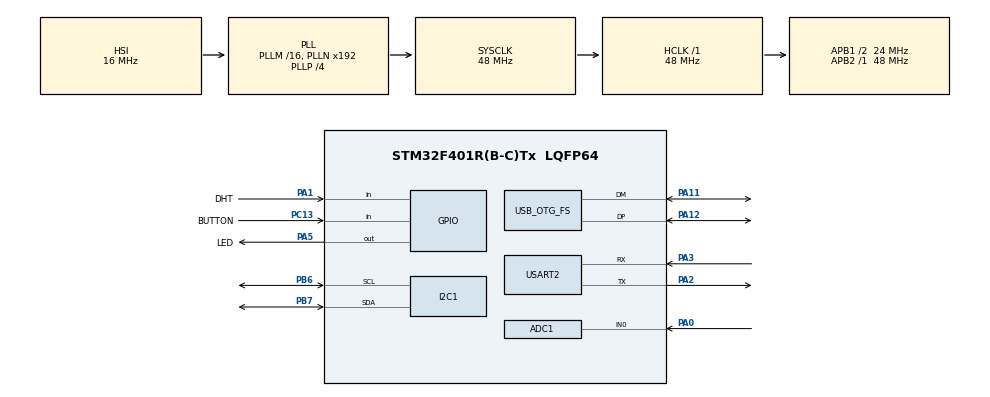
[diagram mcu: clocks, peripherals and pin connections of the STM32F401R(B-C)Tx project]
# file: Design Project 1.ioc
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ADC1.Channel-0\#ChannelRegularConversion=ADC_CHANNEL_0
ADC1.NbrOfConversionFlag=1
ADC1.Rank-0\#ChannelRegularConversion=1
ADC1.SamplingTime-0\#ChannelRegularConversion=ADC_SAMPLETIME_3CYCLES
ADC1.master=1
FREERTOS.Tasks01=defaultTask,24,128,StartDefaultTask,Default,NULL,Dynamic,NULL,NULL
Mcu.Family=STM32F4
Mcu.Name=STM32F401R(B-C)Tx
Mcu.Package=LQFP64
NVIC.OTG_FS_IRQn=true\:5\:0\:false\:false\:true\:true\:false\:true\:true
NVIC.PriorityGroup=NVIC_PRIORITYGROUP_4
NVIC.USART2_IRQn=true\:5\:0\:false\:false\:true\:true\:true\:true\:true
PA0-WKUP.Signal=ADCx_IN0
PA1.GPIO_Label=DHT
PA1.GPIO_PuPd=GPIO_PULLUP
PA1.Signal=GPIO_Input
PA11.Mode=Device_Only
PA11.Signal=USB_OTG_FS_DM
PA12.Mode=Device_Only
PA12.Signal=USB_OTG_FS_DP
PA2.Mode=Asynchronous
PA2.Signal=USART2_TX
PA3.Mode=Asynchronous
PA3.Signal=USART2_RX
PA5.GPIO_Label=LED
PA5.Signal=GPIO_Output
PB6.Mode=I2C
PB6.Signal=I2C1_SCL
PB7.Mode=I2C
PB7.Signal=I2C1_SDA
PC13-ANTI_TAMP.GPIO_Label=BUTTON
PC13-ANTI_TAMP.GPIO_PuPd=GPIO_PULLUP
PC13-ANTI_TAMP.Signal=GPIO_Input
ProjectManager.HeapSize=0x200
ProjectManager.StackSize=0x400
ProjectManager.TargetToolchain=STM32CubeIDE
RCC.AHBFreq_Value=48000000
RCC.APB1CLKDivider=RCC_HCLK_DIV2
RCC.APB1Freq_Value=24000000
RCC.APB1TimFreq_Value=48000000
RCC.APB2Freq_Value=48000000
RCC.APB2TimFreq_Value=48000000
RCC.CortexFreq_Value=48000000
RCC.HCLKFreq_Value=48000000
RCC.HSE_VALUE=25000000
RCC.HSI_VALUE=16000000
RCC.LSE_VALUE=32768
RCC.PLLP=RCC_PLLP_DIV4
RCC.PLLSource=RCC_PLLSOURCE_HSI
RCC.PLLSourceVirtualString=RCC_PLLSOURCE_HSI
RCC.SYSCLKFreq_VALUE=48000000
RCC.SYSCLKSource=RCC_SYSCLKSOURCE_PLLCLK
RCC.VCOOutputFreq_Value=192000000
SH.ADCx_IN0.0=ADC1_IN0,IN0
TIM10.Prescaler=83
USART2.VirtualMode=VM_ASYNC
USB_DEVICE.CLASS_NAME_FS=CDC
USB_DEVICE.VirtualMode=Cdc
USB_DEVICE.VirtualModeFS=Cdc_FS
USB_OTG_FS.VirtualMode=Device_Only
VP_FREERTOS_VS_CMSIS_V2.Mode=CMSIS_V2
VP_TIM10_VS_ClockSourceINT.Mode=Enable_Timer
VP_USB_DEVICE_VS_USB_DEVICE_CDC_FS.Mode=CDC_FS
board=custom

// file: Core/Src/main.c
/* USER CODE BEGIN Header */
/**
  ******************************************************************************
  * @file           : main.c
  * @brief          : Main program body
  ******************************************************************************
  */
/* USER CODE END Header */
#include "main.h"
#include "cmsis_os.h"
#include "adc.h"
#include "i2c.h"
#include "tim.h"
#include "usart.h"
#include "usb_device.h"
#include "gpio.h"

/* USER CODE BEGIN Includes */
#include "i2c-lcd.h"
#include <stdio.h>
#include <string.h>
/* USER CODE END Includes */

void SystemClock_Config(void);
void MX_FREERTOS_Init(void);

int main(void)
{

  /* MCU Configuration--------------------------------------------------------*/

  /* Reset of all peripherals, Initializes the Flash interface and the Systick. */
  HAL_Init();

  /* Configure the system clock */
  SystemClock_Config();

  /* Initialize all configured peripherals */
  MX_GPIO_Init();
  MX_USART2_UART_Init();
  MX_ADC1_Init();
  MX_TIM10_Init();
  MX_I2C1_Init();
  /* USER CODE BEGIN 2 */
  // LCD welcome screen (optional)

  /* USER CODE END 2 */

  /* Init scheduler */
  osKernelInitialize();

  /* Call init function for freertos objects (in cmsis_os2.c) */
  MX_FREERTOS_Init();

  /* Start scheduler */
  osKernelStart();

  /* We should never get here as control is now taken by the scheduler */

  /* Infinite loop */
  while (1)
  {

  }
}

void SystemClock_Config(void)
{
  RCC_OscInitTypeDef RCC_OscInitStruct = {0};
  RCC_ClkInitTypeDef RCC_ClkInitStruct = {0};

  /** Configure the main internal regulator output voltage
  */
  __HAL_RCC_PWR_CLK_ENABLE();
  __HAL_PWR_VOLTAGESCALING_CONFIG(PWR_REGULATOR_VOLTAGE_SCALE2);

  /** Initializes the RCC Oscillators according to the specified parameters
  * in the RCC_OscInitTypeDef structure.
  */
  RCC_OscInitStruct.OscillatorType = RCC_OSCILLATORTYPE_HSI;
  RCC_OscInitStruct.HSIState = RCC_HSI_ON;
  RCC_OscInitStruct.HSICalibrationValue = RCC_HSICALIBRATION_DEFAULT;
  RCC_OscInitStruct.PLL.PLLState = RCC_PLL_ON;
  RCC_OscInitStruct.PLL.PLLSource = RCC_PLLSOURCE_HSI;
  RCC_OscInitStruct.PLL.PLLM = 16;
  RCC_OscInitStruct.PLL.PLLN = 192;
  RCC_OscInitStruct.PLL.PLLP = RCC_PLLP_DIV4;
  RCC_OscInitStruct.PLL.PLLQ = 4;
  if (HAL_RCC_OscConfig(&RCC_OscInitStruct) != HAL_OK)
  {
    Error_Handler();
  }

  /** Initializes the CPU, AHB and APB buses clocks
  */
  RCC_ClkInitStruct.ClockType = RCC_CLOCKTYPE_HCLK|RCC_CLOCKTYPE_SYSCLK
                              |RCC_CLOCKTYPE_PCLK1|RCC_CLOCKTYPE_PCLK2;
  RCC_ClkInitStruct.SYSCLKSource = RCC_SYSCLKSOURCE_PLLCLK;
  RCC_ClkInitStruct.AHBCLKDivider = RCC_SYSCLK_DIV1;
  RCC_ClkInitStruct.APB1CLKDivider = RCC_HCLK_DIV2;
  RCC_ClkInitStruct.APB2CLKDivider = RCC_HCLK_DIV1;

  if (HAL_RCC_ClockConfig(&RCC_ClkInitStruct, FLASH_LATENCY_1) != HAL_OK)
  {
    Error_Handler();
  }
}

void Error_Handler(void)
{
  __disable_irq();
  while (1)
  {
  }
}

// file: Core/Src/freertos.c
#include "cmsis_os2.h"
#include "main.h"
#include "adc.h"
#include "gpio.h"
#include "usb_device.h"
#include "usbd_cdc_if.h"
#include "dht.h"
#include "i2c-lcd.h"
#include "i2c.h"
#include <stdio.h>
#include <string.h>

/* Thresholds */
#define TEMP_ALERT_HIGH     35
#define HUM_ALERT_HIGH      80
#define LIGHT_ALERT_LOW     10
#define LIGHT_ALERT_HIGH    90

/* Task handles */
osThreadId_t sensorTaskHandle;
osThreadId_t displayTaskHandle;
osThreadId_t buttonTaskHandle;

/* Queue handle */
osMessageQueueId_t sensorQueueHandle;

/* Display mode */
volatile uint8_t displayMode = 1;

/* Max recorded values */
uint8_t maxTemp = 0, maxHum = 0, maxLight = 0;

/* Struct for sensor readings */
typedef struct {
  uint8_t temp;
  uint8_t hum;
  uint8_t lightPercent;
  uint16_t rawTemp;
  uint16_t rawHum;
  uint16_t adcValue;
  uint8_t dhtStatus;
  uint8_t ldrStatus;
} SensorData_t;

/* Task prototypes */
void SensorTask(void *argument);
void DisplayTask(void *argument);
void ButtonTask(void *argument);

void MX_FREERTOS_Init(void)
{
    const osThreadAttr_t sensorTask_attributes = {
        .name = "SensorTask",
        .stack_size = 128 * 4,
        .priority = (osPriority_t) osPriorityNormal,
    };
    sensorTaskHandle = osThreadNew(SensorTask, NULL, &sensorTask_attributes);

    const osThreadAttr_t displayTask_attributes = {
        .name = "DisplayTask",
        .stack_size = 128 * 4,
        .priority = (osPriority_t) osPriorityBelowNormal,
    };
    displayTaskHandle = osThreadNew(DisplayTask, NULL, &displayTask_attributes);

    const osThreadAttr_t buttonTask_attributes = {
        .name = "ButtonTask",
        .stack_size = 128 * 4,
        .priority = (osPriority_t) osPriorityLow,
    };
    buttonTaskHandle = osThreadNew(ButtonTask, NULL, &buttonTask_attributes);

    sensorQueueHandle = osMessageQueueNew(4, sizeof(SensorData_t), NULL);
}

/* Sensor task */
void SensorTask(void *argument)
{
    MX_USB_DEVICE_Init();
    DHT_Init();
    char msg[64];

    for (;;)
    {
        SensorData_t data;
        HAL_GPIO_TogglePin(LED_GPIO_Port, LED_Pin);

        HAL_ADC_Start(&hadc1);
        if (HAL_ADC_PollForConversion(&hadc1, HAL_MAX_DELAY) == HAL_OK)
        {
            data.adcValue = HAL_ADC_GetValue(&hadc1);
            data.lightPercent = (data.adcValue * 100) / 4095;
            data.ldrStatus = (data.lightPercent > 1 && data.lightPercent < 99);
        }
        HAL_ADC_Stop(&hadc1);

        if (DHT_Read(&data.hum, &data.temp) == 0)
        {
            data.dhtStatus = 1;
            data.rawHum = data.hum * 10;
            data.rawTemp = data.temp * 10;

            if (data.temp > maxTemp) maxTemp = data.temp;
            if (data.hum > maxHum) maxHum = data.hum;
            if (data.lightPercent > maxLight) maxLight = data.lightPercent;

            snprintf(msg, sizeof(msg), "Temp: %dC  Hum: %d%%  Light: %d%%\r\n", data.temp, data.hum, data.lightPercent);
        }
        else
        {
            data.dhtStatus = 0;
            snprintf(msg, sizeof(msg), "DHT sensor error\r\n");
        }

        CDC_Transmit_FS((uint8_t *)msg, strlen(msg));
        osMessageQueuePut(sensorQueueHandle, &data, 0, 0);
        osDelay(1000);
    }
}

/* Display task */
void DisplayTask(void *argument)
{
    osDelay(500);
    HAL_I2C_DeInit(&hi2c1);
    HAL_I2C_Init(&hi2c1);
    osDelay(10);
    lcd_init();
    osDelay(50);
    lcd_clear();
    osDelay(10);
    lcd_clear();
    osDelay(10);

    SensorData_t data;

    for (;;)
    {
        lcd_clear();

        char line1[17], line2[17], lbuf[14];
        char lcdAlert1[17] = "";
        char lcdAlert2[17] = "";
        uint8_t showAlert = 0;

        if (osMessageQueueGet(sensorQueueHandle, &data, NULL, 100) == osOK)
        {
            if (!data.dhtStatus) {
                snprintf(lcdAlert1, sizeof(lcdAlert1), "DHT SENSOR ERROR");
                CDC_Transmit_FS((uint8_t *)"ALERT: DHT SENSOR ERROR\r\n", strlen("ALERT: DHT SENSOR ERROR\r\n"));
                showAlert = 1;
            }
            else if (!data.ldrStatus) {
                snprintf(lcdAlert1, sizeof(lcdAlert1), "LDR SENSOR ERROR");
                CDC_Transmit_FS((uint8_t *)"ALERT: LDR SENSOR ERROR\r\n", strlen("ALERT: LDR SENSOR ERROR\r\n"));
                showAlert = 1;
            }
            else {
                if (data.temp > TEMP_ALERT_HIGH) {
                    snprintf(lcdAlert1, sizeof(lcdAlert1), "TEMP TOO HIGH");
                    CDC_Transmit_FS((uint8_t *)"ALERT: TEMP TOO HIGH\r\n", strlen("ALERT: TEMP TOO HIGH\r\n"));
                    showAlert = 1;
                }
                if (data.hum > HUM_ALERT_HIGH) {
                    if (showAlert && strlen(lcdAlert2) == 0)
                        snprintf(lcdAlert2, sizeof(lcdAlert2), "HUMIDITY TOO HIGH");
                    else if (!showAlert)
                        snprintf(lcdAlert1, sizeof(lcdAlert1), "HUMIDITY TOO HIGH");
                    CDC_Transmit_FS((uint8_t *)"ALERT: HUMIDITY TOO HIGH\r\n", strlen("ALERT: HUMIDITY TOO HIGH\r\n"));
                    showAlert = 1;
                }
                if (data.lightPercent < LIGHT_ALERT_LOW) {
                    if (showAlert && strlen(lcdAlert2) == 0)
                        snprintf(lcdAlert2, sizeof(lcdAlert2), "LIGHT LEVEL LOW");
                    else if (!showAlert)
                        snprintf(lcdAlert1, sizeof(lcdAlert1), "LIGHT LEVEL LOW");
                    CDC_Transmit_FS((uint8_t *)"ALERT: LIGHT LEVEL LOW\r\n", strlen("ALERT: LIGHT LEVEL LOW\r\n"));
                    showAlert = 1;
                }
                else if (data.lightPercent > LIGHT_ALERT_HIGH) {
                    if (showAlert && strlen(lcdAlert2) == 0)
                        snprintf(lcdAlert2, sizeof(lcdAlert2), "LIGHT LEVEL HIGH");
                    else if (!showAlert)
                        snprintf(lcdAlert1, sizeof(lcdAlert1), "LIGHT LEVEL HIGH");
                    CDC_Transmit_FS((uint8_t *)"ALERT: LIGHT LEVEL HIGH\r\n", strlen("ALERT: LIGHT LEVEL HIGH\r\n"));
                    showAlert = 1;
                }
            }

            if (showAlert)
            {
                lcd_clear();
                lcd_put_cur(0, 0); lcd_send_string(lcdAlert1);
                lcd_put_cur(1, 0); lcd_send_string(lcdAlert2[0] ? lcdAlert2 : "CHECK SYSTEM");
                osDelay(1000);
                lcd_clear();
            }

            if (displayMode == 1) {
                snprintf(line1, sizeof(line1), "T:%03u H:%03u", data.rawTemp, data.rawHum);
                snprintf(lbuf, sizeof(lbuf), "L:%lu", (unsigned long)data.adcValue);
                snprintf(line2, sizeof(line2), "%-13s[1]", lbuf);
            }
            else if (displayMode == 2) {
                snprintf(line1, sizeof(line1), "T:%02d\xDF""C H:%02d%%", data.temp, data.hum);
                snprintf(lbuf, sizeof(lbuf), "L:%d%%", data.lightPercent);
                snprintf(line2, sizeof(line2), "%-13s[2]", lbuf);
            }
            else if (displayMode == 3) {
                snprintf(line1, sizeof(line1), "T:%02d\xDF""C H:%02d%%", maxTemp, maxHum);
                snprintf(lbuf, sizeof(lbuf), "L:%d%%", maxLight);
                snprintf(line2, sizeof(line2), "%-13s[3]", lbuf);
            }
            else {
                snprintf(line1, sizeof(line1), "DHT:%s LDR:%s",
                         data.dhtStatus ? "OK" : "FAIL",
                         data.ldrStatus ? "OK" : "FAIL");
                snprintf(line2, sizeof(line2), "System Running");
            }

            lcd_put_cur(0, 0); lcd_send_string(line1);
            lcd_put_cur(1, 0); lcd_send_string(line2);
        }

        osDelay(1000);
    }
}

/* Button task */
void ButtonTask(void *argument)
{
    uint8_t lastButtonState = 1;
    for (;;)
    {
        uint8_t buttonState = HAL_GPIO_ReadPin(BUTTON_GPIO_Port, BUTTON_Pin);
        if (lastButtonState == 1 && buttonState == 0)
        {
            displayMode++;
            if (displayMode > 4) displayMode = 1;
        }
        lastButtonState = buttonState;
        osDelay(50);
    }
}
